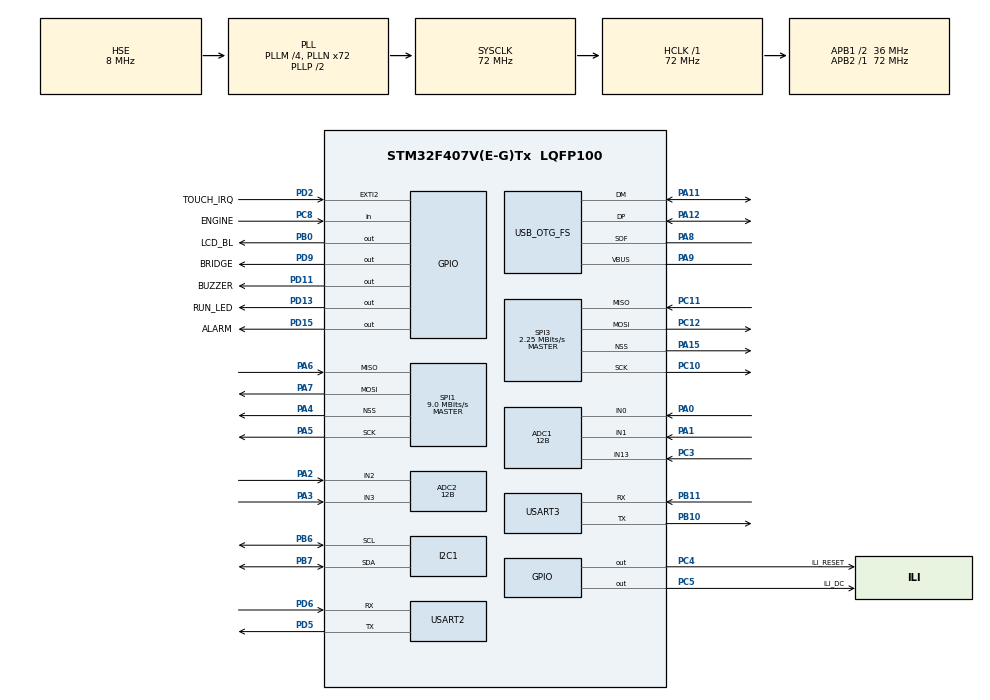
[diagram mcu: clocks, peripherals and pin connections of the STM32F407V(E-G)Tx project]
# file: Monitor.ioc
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ADC1.Channel-22\#ChannelRegularConversion=ADC_CHANNEL_0
ADC1.ClockPrescaler=ADC_CLOCK_SYNC_PCLK_DIV4
ADC1.ContinuousConvMode=DISABLE
ADC1.DMAContinuousRequests=DISABLE
ADC1.DataAlign=ADC_DATAALIGN_RIGHT
ADC1.DiscontinuousConvMode=DISABLE
ADC1.EOCSelection=ADC_EOC_SINGLE_CONV
ADC1.EnableAnalogWatchDog=false
ADC1.ExternalTrigConv=ADC_SOFTWARE_START
ADC1.ExternalTrigConvEdge=ADC_EXTERNALTRIGCONVEDGE_NONE
ADC1.InjNumberOfConversion=0
ADC1.NbrOfConversion=1
ADC1.NbrOfConversionFlag=1
ADC1.Rank-22\#ChannelRegularConversion=1
ADC1.Resolution=ADC_RESOLUTION_12B
ADC1.SamplingTime-22\#ChannelRegularConversion=ADC_SAMPLETIME_3CYCLES
ADC1.ScanConvMode=DISABLE
ADC1.master=1
ADC2.Channel-32\#ChannelRegularConversion=ADC_CHANNEL_2
ADC2.ClockPrescaler=ADC_CLOCK_SYNC_PCLK_DIV4
ADC2.ContinuousConvMode=DISABLE
ADC2.DMAContinuousRequests=DISABLE
ADC2.DataAlign=ADC_DATAALIGN_RIGHT
ADC2.DiscontinuousConvMode=DISABLE
ADC2.EOCSelection=ADC_EOC_SINGLE_CONV
ADC2.EnableAnalogWatchDog=false
ADC2.ExternalTrigConv=ADC_SOFTWARE_START
ADC2.ExternalTrigConvEdge=ADC_EXTERNALTRIGCONVEDGE_NONE
ADC2.InjNumberOfConversion=0
ADC2.NbrOfConversion=1
ADC2.NbrOfConversionFlag=1
ADC2.Rank-32\#ChannelRegularConversion=1
ADC2.Resolution=ADC_RESOLUTION_12B
ADC2.SamplingTime-32\#ChannelRegularConversion=ADC_SAMPLETIME_3CYCLES
ADC2.ScanConvMode=DISABLE
Dma.Request0=SPI1_TX
Dma.SPI1_TX.0.Direction=DMA_MEMORY_TO_PERIPH
Dma.SPI1_TX.0.FIFOMode=DMA_FIFOMODE_DISABLE
Dma.SPI1_TX.0.Instance=DMA2_Stream3
Dma.SPI1_TX.0.MemDataAlignment=DMA_MDATAALIGN_BYTE
Dma.SPI1_TX.0.MemInc=DMA_MINC_ENABLE
Dma.SPI1_TX.0.Mode=DMA_NORMAL
Dma.SPI1_TX.0.PeriphDataAlignment=DMA_PDATAALIGN_BYTE
Dma.SPI1_TX.0.PeriphInc=DMA_PINC_DISABLE
Dma.SPI1_TX.0.Priority=DMA_PRIORITY_MEDIUM
FREERTOS.Queues01=displayQueue,16,uint32_t,0,Dynamic,NULL,NULL
FREERTOS.Tasks01=idleTask,-3,128,StartIdleTask,Default,NULL,Dynamic,NULL,NULL;displayTask,0,512,StartDisplayTask,As external,NULL,Dynamic,NULL,NULL;touchTask,-2,256,StartTouchTask,As external,NULL,Dynamic,NULL,NULL;measureTask,1,512,StartMeasureTask,As external,NULL,Dynamic,NULL,NULL
Mcu.Family=STM32F4
Mcu.Name=STM32F407V(E-G)Tx
Mcu.Package=LQFP100
NVIC.DMA2_Stream3_IRQn=true\:5\:0\:false\:false\:true\:true\:false
NVIC.EXTI2_IRQn=true\:5\:0\:true\:true\:true\:2\:true\:true
NVIC.OTG_FS_IRQn=true\:5\:0\:false\:false\:true\:true\:false
NVIC.PriorityGroup=NVIC_PRIORITYGROUP_4
NVIC.TIM1_UP_TIM10_IRQn=true\:0\:0\:false\:false\:true\:false\:false
NVIC.TIM4_IRQn=true\:5\:0\:false\:true\:true\:1\:true\:true
NVIC.TimeBase=TIM1_UP_TIM10_IRQn
NVIC.TimeBaseIP=TIM1
PA0-WKUP.Signal=ADCx_IN0
PA1.Signal=ADCx_IN1
PA11.Mode=Device_Only
PA11.Signal=USB_OTG_FS_DM
PA12.Mode=Device_Only
PA12.Signal=USB_OTG_FS_DP
PA13.Mode=Serial_Wire
PA13.Signal=SYS_JTMS-SWDIO
PA14.Mode=Serial_Wire
PA14.Signal=SYS_JTCK-SWCLK
PA15.GPIO_Speed=GPIO_SPEED_FREQ_HIGH
PA15.Mode=NSS_Signal_Hard_Output
PA15.Signal=SPI3_NSS
PA2.Signal=ADCx_IN2
PA3.Signal=ADCx_IN3
PA4.Mode=NSS_Signal_Hard_Output
PA4.Signal=SPI1_NSS
PA5.Mode=Full_Duplex_Master
PA5.Signal=SPI1_SCK
PA6.Mode=Full_Duplex_Master
PA6.Signal=SPI1_MISO
PA7.Mode=Full_Duplex_Master
PA7.Signal=SPI1_MOSI
PA8.Mode=Activate_SOF_FS
PA8.Signal=USB_OTG_FS_SOF
PA9.Mode=Activate_VBUS
PA9.Signal=USB_OTG_FS_VBUS
PB0.GPIO_Label=LCD_BL
PB0.Signal=GPIO_Output
PB10.Mode=Asynchronous
PB10.Signal=USART3_TX
PB11.Mode=Asynchronous
PB11.Signal=USART3_RX
PB6.Mode=I2C
PB6.Signal=I2C1_SCL
PB7.Mode=I2C
PB7.Signal=I2C1_SDA
PC10.GPIO_Speed=GPIO_SPEED_FREQ_HIGH
PC10.Mode=Full_Duplex_Master
PC10.Signal=SPI3_SCK
PC11.GPIO_Speed=GPIO_SPEED_FREQ_HIGH
PC11.Mode=Full_Duplex_Master
PC11.Signal=SPI3_MISO
PC12.GPIO_Speed=GPIO_SPEED_FREQ_HIGH
PC12.Mode=Full_Duplex_Master
PC12.Signal=SPI3_MOSI
PC14-OSC32_IN.Mode=LSE-External-Oscillator
PC14-OSC32_IN.Signal=RCC_OSC32_IN
PC15-OSC32_OUT.Mode=LSE-External-Oscillator
PC15-OSC32_OUT.Signal=RCC_OSC32_OUT
PC3.Signal=ADCx_IN13
PC4.GPIO_Label=ILI_RESET
PC4.Signal=GPIO_Output
PC5.GPIO_Label=ILI_DC
PC5.Signal=GPIO_Output
PC8.GPIO_Label=ENGINE
PC8.Signal=GPIO_Input
PD11.GPIO_Label=BUZZER
PD11.Signal=GPIO_Output
PD13.GPIO_Label=RUN_LED
PD13.Signal=GPIO_Output
PD15.GPIO_Label=ALARM
PD15.Signal=GPIO_Output
PD2.GPIO_Label=TOUCH_IRQ
PD2.GPIO_ModeDefaultEXTI=GPIO_MODE_IT_FALLING
PD2.GPIO_PuPd=GPIO_NOPULL
PD2.Signal=GPXTI2
PD5.Mode=Asynchronous
PD5.Signal=USART2_TX
PD6.Mode=Asynchronous
PD6.Signal=USART2_RX
PD9.GPIO_Label=BRIDGE
PD9.Signal=GPIO_Output
PH0-OSC_IN.Mode=HSE-External-Oscillator
PH0-OSC_IN.Signal=RCC_OSC_IN
PH1-OSC_OUT.Mode=HSE-External-Oscillator
PH1-OSC_OUT.Signal=RCC_OSC_OUT
ProjectManager.HeapSize=0x200
ProjectManager.StackSize=0x400
ProjectManager.TargetToolchain=SW4STM32
RCC.48MHZClocksFreq_Value=48000000
RCC.AHBFreq_Value=72000000
RCC.APB1CLKDivider=RCC_HCLK_DIV2
RCC.APB1Freq_Value=36000000
RCC.APB1TimFreq_Value=72000000
RCC.APB2Freq_Value=72000000
RCC.APB2TimFreq_Value=72000000
RCC.CortexFreq_Value=72000000
RCC.DATA_CACHE_ENABLE=1
RCC.HCLKFreq_Value=72000000
RCC.HSE_VALUE=8000000
RCC.HSI_VALUE=16000000
RCC.INSTRUCTION_CACHE_ENABLE=1
RCC.PLLM=4
RCC.PLLN=72
RCC.PLLQ=3
RCC.PREFETCH_ENABLE=1
RCC.SYSCLKFreq_VALUE=72000000
RCC.SYSCLKSource=RCC_SYSCLKSOURCE_PLLCLK
RCC.VCOOutputFreq_Value=144000000
SH.ADCx_IN0.0=ADC1_IN0,IN0
SH.ADCx_IN1.0=ADC1_IN1,IN1
SH.ADCx_IN13.0=ADC1_IN13,IN13
SH.ADCx_IN2.0=ADC2_IN2,IN2
SH.ADCx_IN3.0=ADC2_IN3,IN3
SPI1.BaudRatePrescaler=SPI_BAUDRATEPRESCALER_8
SPI1.CalculateBaudRate=9.0 MBits/s
SPI1.Direction=SPI_DIRECTION_2LINES
SPI1.Mode=SPI_MODE_MASTER
SPI1.VirtualNSS=VM_NSSHARD
SPI1.VirtualType=VM_MASTER
SPI3.BaudRatePrescaler=SPI_BAUDRATEPRESCALER_16
SPI3.CalculateBaudRate=2.25 MBits/s
SPI3.Direction=SPI_DIRECTION_2LINES
SPI3.Mode=SPI_MODE_MASTER
SPI3.VirtualNSS=VM_NSSHARD
SPI3.VirtualType=VM_MASTER
TIM4.ClockDivision=TIM_CLOCKDIVISION_DIV1
TIM4.CounterMode=TIM_COUNTERMODE_UP
TIM4.Period=10000-1
TIM4.Prescaler=7200-1
USART2.VirtualMode=VM_ASYNC
USART3.VirtualMode=VM_ASYNC
USB_DEVICE.CLASS_NAME_FS=CDC
USB_DEVICE.MANUFACTURER_STRING-CDC_FS=ioko.eu
USB_DEVICE.PRODUCT_STRING_CDC_FS=ioko monitor
USB_DEVICE.VirtualMode-CDC_FS=Cdc
USB_DEVICE.VirtualModeFS=Cdc_FS
USB_OTG_FS.VirtualMode=Device_Only
VP_ADC1_TempSens_Input.Mode=IN-TempSens
VP_ADC1_Vbat_Input.Mode=IN-Vbat
VP_ADC1_Vref_Input.Mode=IN-Vrefint
VP_FREERTOS_VS_ENABLE.Mode=Enabled
VP_RTC_VS_RTC_Activate.Mode=RTC_Enabled
VP_SYS_VS_tim1.Mode=TIM1
VP_TIM4_VS_ClockSourceINT.Mode=Internal
VP_USB_DEVICE_VS_USB_DEVICE_CDC_FS.Mode=CDC_FS
board=custom

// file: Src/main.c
/**
  ******************************************************************************
  * @file           : main.c
  * @brief          : Main program body
  ******************************************************************************
  * This notice applies to any and all portions of this file
  * that are not between comment pairs USER CODE BEGIN and
  * USER CODE END. Other portions of this file, whether
  * inserted by the user or by software development tools
  * are owned by their respective copyright owners.
  *
  * Copyright (c) 2018 STMicroelectronics International N.V.
  * All rights reserved.
  *
  * Redistribution and use in source and binary forms, with or without
  * modification, are permitted, provided that the following conditions are met:
  *
  * 1. Redistribution of source code must retain the above copyright notice,
  *    this list of conditions and the following disclaimer.
  * 2. Redistributions in binary form must reproduce the above copyright notice,
  *    this list of conditions and the following disclaimer in the documentation
  *    and/or other materials provided with the distribution.
  * 3. Neither the name of STMicroelectronics nor the names of other
  *    contributors to this software may be used to endorse or promote products
  *    derived from this software without specific written permission.
  * 4. This software, including modifications and/or derivative works of this
  *    software, must execute solely and exclusively on microcontroller or
  *    microprocessor devices manufactured by or for STMicroelectronics.
  * 5. Redistribution and use of this software other than as permitted under
  *    this license is void and will automatically terminate your rights under
  *    this license.
  *
  * THIS SOFTWARE IS PROVIDED BY STMICROELECTRONICS AND CONTRIBUTORS "AS IS"
  * AND ANY EXPRESS, IMPLIED OR STATUTORY WARRANTIES, INCLUDING, BUT NOT
  * LIMITED TO, THE IMPLIED WARRANTIES OF MERCHANTABILITY, FITNESS FOR A
  * PARTICULAR PURPOSE AND NON-INFRINGEMENT OF THIRD PARTY INTELLECTUAL PROPERTY
  * RIGHTS ARE DISCLAIMED TO THE FULLEST EXTENT PERMITTED BY LAW. IN NO EVENT
  * SHALL STMICROELECTRONICS OR CONTRIBUTORS BE LIABLE FOR ANY DIRECT, INDIRECT,
  * INCIDENTAL, SPECIAL, EXEMPLARY, OR CONSEQUENTIAL DAMAGES (INCLUDING, BUT NOT
  * LIMITED TO, PROCUREMENT OF SUBSTITUTE GOODS OR SERVICES; LOSS OF USE, DATA,
  * OR PROFITS; OR BUSINESS INTERRUPTION) HOWEVER CAUSED AND ON ANY THEORY OF
  * LIABILITY, WHETHER IN CONTRACT, STRICT LIABILITY, OR TORT (INCLUDING
  * NEGLIGENCE OR OTHERWISE) ARISING IN ANY WAY OUT OF THE USE OF THIS SOFTWARE,
  * EVEN IF ADVISED OF THE POSSIBILITY OF SUCH DAMAGE.
  *
  ******************************************************************************
  */
#include "main.h"
#include "stm32f4xx_hal.h"
#include "cmsis_os.h"
#include "usb_device.h"

ADC_HandleTypeDef hadc1;
ADC_HandleTypeDef hadc2;

I2C_HandleTypeDef hi2c1;

RTC_HandleTypeDef hrtc;

SPI_HandleTypeDef hspi1;
SPI_HandleTypeDef hspi3;
DMA_HandleTypeDef hdma_spi1_tx;

TIM_HandleTypeDef htim4;

UART_HandleTypeDef huart2;
UART_HandleTypeDef huart3;

osThreadId idleTaskHandle;
osThreadId displayTaskHandle;
osThreadId touchTaskHandle;
osThreadId measureTaskHandle;
osMessageQId displayQueueHandle;

/* USER CODE BEGIN PV */
/* Private variables ---------------------------------------------------------*/

/* USER CODE END PV */

void SystemClock_Config(void);
static void MX_GPIO_Init(void);
static void MX_DMA_Init(void);
static void MX_ADC1_Init(void);
static void MX_ADC2_Init(void);
static void MX_RTC_Init(void);
static void MX_SPI1_Init(void);
static void MX_SPI3_Init(void);
static void MX_USART2_UART_Init(void);
static void MX_USART3_UART_Init(void);
static void MX_I2C1_Init(void);
static void MX_TIM4_Init(void);
void StartIdleTask(void const * argument);
extern void StartDisplayTask(void const * argument);
extern void StartTouchTask(void const * argument);
extern void StartMeasureTask(void const * argument);
static void MX_NVIC_Init(void);

/* USER CODE BEGIN PFP */
/* Private function prototypes -----------------------------------------------*/
extern uint8_t meas_pending;

/* USER CODE END PFP */

int main(void)
{

  /* MCU Configuration----------------------------------------------------------*/

  /* Reset of all peripherals, Initializes the Flash interface and the Systick. */
  HAL_Init();

  /* Configure the system clock */
  SystemClock_Config();

  /* Initialize all configured peripherals */
  MX_GPIO_Init();
  MX_DMA_Init();
  MX_ADC1_Init();
  MX_ADC2_Init();
  MX_RTC_Init();
  MX_SPI1_Init();
  MX_SPI3_Init();
  MX_USART2_UART_Init();
  MX_USART3_UART_Init();
  MX_I2C1_Init();
  MX_TIM4_Init();

  /* Initialize interrupts */
  MX_NVIC_Init();

  /* Create the thread(s) */
  /* definition and creation of idleTask */
  osThreadDef(idleTask, StartIdleTask, osPriorityIdle, 0, 128);
  idleTaskHandle = osThreadCreate(osThread(idleTask), NULL);

  /* definition and creation of displayTask */
  osThreadDef(displayTask, StartDisplayTask, osPriorityNormal, 0, 512);
  displayTaskHandle = osThreadCreate(osThread(displayTask), NULL);

  /* definition and creation of touchTask */
  osThreadDef(touchTask, StartTouchTask, osPriorityLow, 0, 256);
  touchTaskHandle = osThreadCreate(osThread(touchTask), NULL);

  /* definition and creation of measureTask */
  osThreadDef(measureTask, StartMeasureTask, osPriorityAboveNormal, 0, 512);
  measureTaskHandle = osThreadCreate(osThread(measureTask), NULL);

  /* Create the queue(s) */
  /* definition and creation of displayQueue */
/* what about the sizeof here??? cd native code */
  osMessageQDef(displayQueue, 16, uint32_t);
  displayQueueHandle = osMessageCreate(osMessageQ(displayQueue), NULL);

  /* Start scheduler */
  osKernelStart();

  /* We should never get here as control is now taken by the scheduler */

  /* Infinite loop */
  while (1)
  {

  }

}

void SystemClock_Config(void)
{

  RCC_OscInitTypeDef RCC_OscInitStruct;
  RCC_ClkInitTypeDef RCC_ClkInitStruct;
  RCC_PeriphCLKInitTypeDef PeriphClkInitStruct;

    /**Configure the main internal regulator output voltage
    */
  __HAL_RCC_PWR_CLK_ENABLE();

  __HAL_PWR_VOLTAGESCALING_CONFIG(PWR_REGULATOR_VOLTAGE_SCALE1);

    /**Initializes the CPU, AHB and APB busses clocks
    */
  RCC_OscInitStruct.OscillatorType = RCC_OSCILLATORTYPE_LSI|RCC_OSCILLATORTYPE_HSE;
  RCC_OscInitStruct.HSEState = RCC_HSE_ON;
  RCC_OscInitStruct.LSIState = RCC_LSI_ON;
  RCC_OscInitStruct.PLL.PLLState = RCC_PLL_ON;
  RCC_OscInitStruct.PLL.PLLSource = RCC_PLLSOURCE_HSE;
  RCC_OscInitStruct.PLL.PLLM = 4;
  RCC_OscInitStruct.PLL.PLLN = 72;
  RCC_OscInitStruct.PLL.PLLP = RCC_PLLP_DIV2;
  RCC_OscInitStruct.PLL.PLLQ = 3;
  if (HAL_RCC_OscConfig(&RCC_OscInitStruct) != HAL_OK)
  {
    _Error_Handler(__FILE__, __LINE__);
  }

    /**Initializes the CPU, AHB and APB busses clocks
    */
  RCC_ClkInitStruct.ClockType = RCC_CLOCKTYPE_HCLK|RCC_CLOCKTYPE_SYSCLK
                              |RCC_CLOCKTYPE_PCLK1|RCC_CLOCKTYPE_PCLK2;
  RCC_ClkInitStruct.SYSCLKSource = RCC_SYSCLKSOURCE_PLLCLK;
  RCC_ClkInitStruct.AHBCLKDivider = RCC_SYSCLK_DIV1;
  RCC_ClkInitStruct.APB1CLKDivider = RCC_HCLK_DIV2;
  RCC_ClkInitStruct.APB2CLKDivider = RCC_HCLK_DIV1;

  if (HAL_RCC_ClockConfig(&RCC_ClkInitStruct, FLASH_LATENCY_2) != HAL_OK)
  {
    _Error_Handler(__FILE__, __LINE__);
  }

  PeriphClkInitStruct.PeriphClockSelection = RCC_PERIPHCLK_RTC;
  PeriphClkInitStruct.RTCClockSelection = RCC_RTCCLKSOURCE_LSI;
  if (HAL_RCCEx_PeriphCLKConfig(&PeriphClkInitStruct) != HAL_OK)
  {
    _Error_Handler(__FILE__, __LINE__);
  }

    /**Configure the Systick interrupt time
    */
  HAL_SYSTICK_Config(HAL_RCC_GetHCLKFreq()/1000);

    /**Configure the Systick
    */
  HAL_SYSTICK_CLKSourceConfig(SYSTICK_CLKSOURCE_HCLK);

  /* SysTick_IRQn interrupt configuration */
  HAL_NVIC_SetPriority(SysTick_IRQn, 15, 0);
}

/**
  * @brief NVIC Configuration.
  * @retval None
  */
static void MX_NVIC_Init(void)
{
  /* TIM4_IRQn interrupt configuration */
  HAL_NVIC_SetPriority(TIM4_IRQn, 5, 0);
  HAL_NVIC_EnableIRQ(TIM4_IRQn);
  /* EXTI2_IRQn interrupt configuration */
  HAL_NVIC_SetPriority(EXTI2_IRQn, 5, 0);
  HAL_NVIC_EnableIRQ(EXTI2_IRQn);
}

/* ADC1 init function */
static void MX_ADC1_Init(void)
{

  ADC_ChannelConfTypeDef sConfig;

    /**Configure the global features of the ADC (Clock, Resolution, Data Alignment and number of conversion)
    */
  hadc1.Instance = ADC1;
  hadc1.Init.ClockPrescaler = ADC_CLOCK_SYNC_PCLK_DIV4;
  hadc1.Init.Resolution = ADC_RESOLUTION_12B;
  hadc1.Init.ScanConvMode = DISABLE;
  hadc1.Init.ContinuousConvMode = DISABLE;
  hadc1.Init.DiscontinuousConvMode = DISABLE;
  hadc1.Init.ExternalTrigConvEdge = ADC_EXTERNALTRIGCONVEDGE_NONE;
  hadc1.Init.ExternalTrigConv = ADC_SOFTWARE_START;
  hadc1.Init.DataAlign = ADC_DATAALIGN_RIGHT;
  hadc1.Init.NbrOfConversion = 1;
  hadc1.Init.DMAContinuousRequests = DISABLE;
  hadc1.Init.EOCSelection = ADC_EOC_SINGLE_CONV;
  if (HAL_ADC_Init(&hadc1) != HAL_OK)
  {
    _Error_Handler(__FILE__, __LINE__);
  }

    /**Configure for the selected ADC regular channel its corresponding rank in the sequencer and its sample time.
    */
  sConfig.Channel = ADC_CHANNEL_0;
  sConfig.Rank = 1;
  sConfig.SamplingTime = ADC_SAMPLETIME_3CYCLES;
  if (HAL_ADC_ConfigChannel(&hadc1, &sConfig) != HAL_OK)
  {
    _Error_Handler(__FILE__, __LINE__);
  }

}

/* ADC2 init function */
static void MX_ADC2_Init(void)
{

  ADC_ChannelConfTypeDef sConfig;

    /**Configure the global features of the ADC (Clock, Resolution, Data Alignment and number of conversion)
    */
  hadc2.Instance = ADC2;
  hadc2.Init.ClockPrescaler = ADC_CLOCK_SYNC_PCLK_DIV4;
  hadc2.Init.Resolution = ADC_RESOLUTION_12B;
  hadc2.Init.ScanConvMode = DISABLE;
  hadc2.Init.ContinuousConvMode = DISABLE;
  hadc2.Init.DiscontinuousConvMode = DISABLE;
  hadc2.Init.ExternalTrigConvEdge = ADC_EXTERNALTRIGCONVEDGE_NONE;
  hadc2.Init.ExternalTrigConv = ADC_SOFTWARE_START;
  hadc2.Init.DataAlign = ADC_DATAALIGN_RIGHT;
  hadc2.Init.NbrOfConversion = 1;
  hadc2.Init.DMAContinuousRequests = DISABLE;
  hadc2.Init.EOCSelection = ADC_EOC_SINGLE_CONV;
  if (HAL_ADC_Init(&hadc2) != HAL_OK)
  {
    _Error_Handler(__FILE__, __LINE__);
  }

    /**Configure for the selected ADC regular channel its corresponding rank in the sequencer and its sample time.
    */
  sConfig.Channel = ADC_CHANNEL_2;
  sConfig.Rank = 1;
  sConfig.SamplingTime = ADC_SAMPLETIME_3CYCLES;
  if (HAL_ADC_ConfigChannel(&hadc2, &sConfig) != HAL_OK)
  {
    _Error_Handler(__FILE__, __LINE__);
  }

}

/* I2C1 init function */
static void MX_I2C1_Init(void)
{

  hi2c1.Instance = I2C1;
  hi2c1.Init.ClockSpeed = 100000;
  hi2c1.Init.DutyCycle = I2C_DUTYCYCLE_2;
  hi2c1.Init.OwnAddress1 = 0;
  hi2c1.Init.AddressingMode = I2C_ADDRESSINGMODE_7BIT;
  hi2c1.Init.DualAddressMode = I2C_DUALADDRESS_DISABLE;
  hi2c1.Init.OwnAddress2 = 0;
  hi2c1.Init.GeneralCallMode = I2C_GENERALCALL_DISABLE;
  hi2c1.Init.NoStretchMode = I2C_NOSTRETCH_DISABLE;
  if (HAL_I2C_Init(&hi2c1) != HAL_OK)
  {
    _Error_Handler(__FILE__, __LINE__);
  }

}

/* RTC init function */
static void MX_RTC_Init(void)
{

    /**Initialize RTC Only
    */
  hrtc.Instance = RTC;
  hrtc.Init.HourFormat = RTC_HOURFORMAT_24;
  hrtc.Init.AsynchPrediv = 127;
  hrtc.Init.SynchPrediv = 255;
  hrtc.Init.OutPut = RTC_OUTPUT_DISABLE;
  hrtc.Init.OutPutPolarity = RTC_OUTPUT_POLARITY_HIGH;
  hrtc.Init.OutPutType = RTC_OUTPUT_TYPE_OPENDRAIN;
  if (HAL_RTC_Init(&hrtc) != HAL_OK)
  {
    _Error_Handler(__FILE__, __LINE__);
  }

}

/* SPI1 init function */
static void MX_SPI1_Init(void)
{

  /* SPI1 parameter configuration*/
  hspi1.Instance = SPI1;
  hspi1.Init.Mode = SPI_MODE_MASTER;
  hspi1.Init.Direction = SPI_DIRECTION_2LINES;
  hspi1.Init.DataSize = SPI_DATASIZE_8BIT;
  hspi1.Init.CLKPolarity = SPI_POLARITY_LOW;
  hspi1.Init.CLKPhase = SPI_PHASE_1EDGE;
  hspi1.Init.NSS = SPI_NSS_HARD_OUTPUT;
  hspi1.Init.BaudRatePrescaler = SPI_BAUDRATEPRESCALER_8;
  hspi1.Init.FirstBit = SPI_FIRSTBIT_MSB;
  hspi1.Init.TIMode = SPI_TIMODE_DISABLE;
  hspi1.Init.CRCCalculation = SPI_CRCCALCULATION_DISABLE;
  hspi1.Init.CRCPolynomial = 10;
  if (HAL_SPI_Init(&hspi1) != HAL_OK)
  {
    _Error_Handler(__FILE__, __LINE__);
  }

}

/* SPI3 init function */
static void MX_SPI3_Init(void)
{

  /* SPI3 parameter configuration*/
  hspi3.Instance = SPI3;
  hspi3.Init.Mode = SPI_MODE_MASTER;
  hspi3.Init.Direction = SPI_DIRECTION_2LINES;
  hspi3.Init.DataSize = SPI_DATASIZE_8BIT;
  hspi3.Init.CLKPolarity = SPI_POLARITY_LOW;
  hspi3.Init.CLKPhase = SPI_PHASE_1EDGE;
  hspi3.Init.NSS = SPI_NSS_HARD_OUTPUT;
  hspi3.Init.BaudRatePrescaler = SPI_BAUDRATEPRESCALER_16;
  hspi3.Init.FirstBit = SPI_FIRSTBIT_MSB;
  hspi3.Init.TIMode = SPI_TIMODE_DISABLE;
  hspi3.Init.CRCCalculation = SPI_CRCCALCULATION_DISABLE;
  hspi3.Init.CRCPolynomial = 10;
  if (HAL_SPI_Init(&hspi3) != HAL_OK)
  {
    _Error_Handler(__FILE__, __LINE__);
  }

}

/* TIM4 init function */
static void MX_TIM4_Init(void)
{

  TIM_ClockConfigTypeDef sClockSourceConfig;
  TIM_MasterConfigTypeDef sMasterConfig;

  htim4.Instance = TIM4;
  htim4.Init.Prescaler = 7200-1;
  htim4.Init.CounterMode = TIM_COUNTERMODE_UP;
  htim4.Init.Period = 10000-1;
  htim4.Init.ClockDivision = TIM_CLOCKDIVISION_DIV1;
  if (HAL_TIM_Base_Init(&htim4) != HAL_OK)
  {
    _Error_Handler(__FILE__, __LINE__);
  }

  sClockSourceConfig.ClockSource = TIM_CLOCKSOURCE_INTERNAL;
  if (HAL_TIM_ConfigClockSource(&htim4, &sClockSourceConfig) != HAL_OK)
  {
    _Error_Handler(__FILE__, __LINE__);
  }

  sMasterConfig.MasterOutputTrigger = TIM_TRGO_RESET;
  sMasterConfig.MasterSlaveMode = TIM_MASTERSLAVEMODE_DISABLE;
  if (HAL_TIMEx_MasterConfigSynchronization(&htim4, &sMasterConfig) != HAL_OK)
  {
    _Error_Handler(__FILE__, __LINE__);
  }

}

/* USART2 init function */
static void MX_USART2_UART_Init(void)
{

  huart2.Instance = USART2;
  huart2.Init.BaudRate = 115200;
  huart2.Init.WordLength = UART_WORDLENGTH_8B;
  huart2.Init.StopBits = UART_STOPBITS_1;
  huart2.Init.Parity = UART_PARITY_NONE;
  huart2.Init.Mode = UART_MODE_TX_RX;
  huart2.Init.HwFlowCtl = UART_HWCONTROL_NONE;
  huart2.Init.OverSampling = UART_OVERSAMPLING_16;
  if (HAL_UART_Init(&huart2) != HAL_OK)
  {
    _Error_Handler(__FILE__, __LINE__);
  }

}

/* USART3 init function */
static void MX_USART3_UART_Init(void)
{

  huart3.Instance = USART3;
  huart3.Init.BaudRate = 115200;
  huart3.Init.WordLength = UART_WORDLENGTH_8B;
  huart3.Init.StopBits = UART_STOPBITS_1;
  huart3.Init.Parity = UART_PARITY_NONE;
  huart3.Init.Mode = UART_MODE_TX_RX;
  huart3.Init.HwFlowCtl = UART_HWCONTROL_NONE;
  huart3.Init.OverSampling = UART_OVERSAMPLING_16;
  if (HAL_UART_Init(&huart3) != HAL_OK)
  {
    _Error_Handler(__FILE__, __LINE__);
  }

}

static void MX_DMA_Init(void)
{
  /* DMA controller clock enable */
  __HAL_RCC_DMA2_CLK_ENABLE();

  /* DMA interrupt init */
  /* DMA2_Stream3_IRQn interrupt configuration */
  HAL_NVIC_SetPriority(DMA2_Stream3_IRQn, 5, 0);
  HAL_NVIC_EnableIRQ(DMA2_Stream3_IRQn);

}

/** Configure pins as
        * Analog
        * Input
        * Output
        * EVENT_OUT
        * EXTI
*/
static void MX_GPIO_Init(void)
{

  GPIO_InitTypeDef GPIO_InitStruct;

  /* GPIO Ports Clock Enable */
  __HAL_RCC_GPIOC_CLK_ENABLE();
  __HAL_RCC_GPIOH_CLK_ENABLE();
  __HAL_RCC_GPIOA_CLK_ENABLE();
  __HAL_RCC_GPIOB_CLK_ENABLE();
  __HAL_RCC_GPIOD_CLK_ENABLE();

  /*Configure GPIO pin Output Level */
  HAL_GPIO_WritePin(GPIOC, ILI_RESET_Pin|ILI_DC_Pin, GPIO_PIN_RESET);

  /*Configure GPIO pin Output Level */
  HAL_GPIO_WritePin(LCD_BL_GPIO_Port, LCD_BL_Pin, GPIO_PIN_RESET);

  /*Configure GPIO pin Output Level */
  HAL_GPIO_WritePin(GPIOD, BRIDGE_Pin|BUZZER_Pin|RUN_LED_Pin|ALARM_Pin, GPIO_PIN_RESET);

  /*Configure GPIO pins : ILI_RESET_Pin ILI_DC_Pin */
  GPIO_InitStruct.Pin = ILI_RESET_Pin|ILI_DC_Pin;
  GPIO_InitStruct.Mode = GPIO_MODE_OUTPUT_PP;
  GPIO_InitStruct.Pull = GPIO_NOPULL;
  GPIO_InitStruct.Speed = GPIO_SPEED_FREQ_LOW;
  HAL_GPIO_Init(GPIOC, &GPIO_InitStruct);

  /*Configure GPIO pin : LCD_BL_Pin */
  GPIO_InitStruct.Pin = LCD_BL_Pin;
  GPIO_InitStruct.Mode = GPIO_MODE_OUTPUT_PP;
  GPIO_InitStruct.Pull = GPIO_NOPULL;
  GPIO_InitStruct.Speed = GPIO_SPEED_FREQ_LOW;
  HAL_GPIO_Init(LCD_BL_GPIO_Port, &GPIO_InitStruct);

  /*Configure GPIO pins : BRIDGE_Pin BUZZER_Pin RUN_LED_Pin ALARM_Pin */
  GPIO_InitStruct.Pin = BRIDGE_Pin|BUZZER_Pin|RUN_LED_Pin|ALARM_Pin;
  GPIO_InitStruct.Mode = GPIO_MODE_OUTPUT_PP;
  GPIO_InitStruct.Pull = GPIO_NOPULL;
  GPIO_InitStruct.Speed = GPIO_SPEED_FREQ_LOW;
  HAL_GPIO_Init(GPIOD, &GPIO_InitStruct);

  /*Configure GPIO pin : ENGINE_Pin */
  GPIO_InitStruct.Pin = ENGINE_Pin;
  GPIO_InitStruct.Mode = GPIO_MODE_INPUT;
  GPIO_InitStruct.Pull = GPIO_NOPULL;
  HAL_GPIO_Init(ENGINE_GPIO_Port, &GPIO_InitStruct);

  /*Configure GPIO pin : TOUCH_IRQ_Pin */
  GPIO_InitStruct.Pin = TOUCH_IRQ_Pin;
  GPIO_InitStruct.Mode = GPIO_MODE_IT_FALLING;
  GPIO_InitStruct.Pull = GPIO_NOPULL;
  HAL_GPIO_Init(TOUCH_IRQ_GPIO_Port, &GPIO_InitStruct);

}

void StartIdleTask(void const * argument)
{
  /* init code for USB_DEVICE */
  MX_USB_DEVICE_Init();

  /* USER CODE BEGIN 5 */
  HAL_TIM_Base_Start_IT(&htim4);

  /* Infinite loop */
  for(;;)
  {
    osDelay(100);
  }
  /* USER CODE END 5 */
}

void HAL_TIM_PeriodElapsedCallback(TIM_HandleTypeDef *htim)
{
  if (htim->Instance == TIM1) {
    HAL_IncTick();
  }
  /* USER CODE BEGIN Callback 1 */
  if (htim->Instance == TIM4) {

      /* 0.1sec timer */
      meas_pending = 1;

  }
  /* USER CODE END Callback 1 */
}

void _Error_Handler(char *file, int line)
{
  while(1)
  {
  }
}

/************************ (C) COPYRIGHT STMicroelectronics *****END OF FILE****/
